# MCU_NAVSS0_UDMAP_0_UDMASS_UDMAP0_CFG_GCFG register map
Vendor: Texas Instruments
Peripheral module from a debugger description file (folder J721S2).
Registers are 32-bit, read-write, reset 0x0 unless marked. A register's access mark holds for its fields unless they carry their own. Offsets are as the file gives them; lines under a group give offsets from that group; [hi:lo] are bit positions; {n}, {i} and the like mark numbered series; 'fields as' and 'values as' point back to an identical list; <NAME> marks a mode.

## MCU_NAVSS0_UDMAP_0_UDMASS_UDMAP0_CFG_GCFG
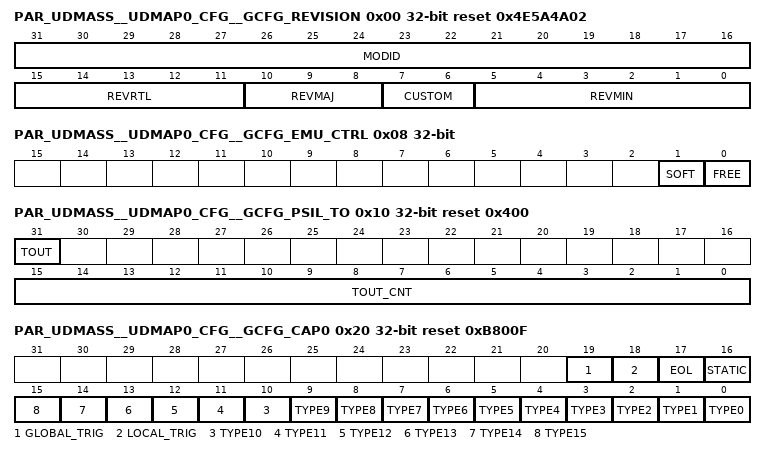
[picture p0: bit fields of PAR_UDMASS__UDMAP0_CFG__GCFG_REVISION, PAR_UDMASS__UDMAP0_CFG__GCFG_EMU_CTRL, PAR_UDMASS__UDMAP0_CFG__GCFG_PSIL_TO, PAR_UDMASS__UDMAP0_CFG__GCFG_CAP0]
0x00 PAR_UDMASS__UDMAP0_CFG__GCFG_REVISION ro reset 0x4E5A4A02 — The Revision Register contains the major and minor revisions for the module.
  [31:16] MODID — Module ID field
  [15:11] REVRTL — RTL revision. Will vary depending on release.
  [10:8] REVMAJ — Major revision
  [7:6] CUSTOM
  [5:0] REVMIN — Minor revision
0x04 PAR_UDMASS__UDMAP0_CFG__GCFG_PERF_CTRL reset 0x40 — The performance control register contains fields which can be used to adjust the performance of the UDMA-P in the system.
  [15:0] TIMEOUT_CNT — This field sets the timeout duration in clock cycles. This field controls the minimum amount of time that an Rx channel will be required to wait when it encounters a buffer starvation condition and the Rx error handling bit is set to 1 (packet is to be preserved - no discard). If the Rx error handling bit in the flow table is cleared, this field will have no effect on the Rx operation. When this field is set to 0, the Rx engine will not force an Rx channel to wait after encountering a starvation event (the feature is disabled). When this field is set to a value other than 0, the Rx engine will force any channel whose associated flow had the Rx error handling bit asserted and which encounters starvation to wait for at least the specified # of clock cycles before coming into context again to check if entries have been added to the Free Queue. This is intended to control potentially debilitating effects on the Rx engine in the UDMAP-P caused by scheduling channels which cannot perform work due to a lack of free descriptor/buffer resources. The exact # of clock cycles between scheduling attempts is not important and will not be exact. The only guarantee is that the # of cycles waited will be at least as large as the timeout_cnt.
0x08 PAR_UDMASS__UDMAP0_CFG__GCFG_EMU_CTRL — The emulation control register is used to control the behavior of the DMA when the emususp input is asserted.
  [1] SOFT, [0] FREE
0x10 PAR_UDMASS__UDMAP0_CFG__GCFG_PSIL_TO reset 0x400 — The PSI-L proxy timeout register controls the timeout watchdog and reports timeout occurrances on PSI-L configuration transactions issued by the built in PSI-L proxy.
  [31] TOUT — Timeout occurred. When set indicates that a timeout has occurred on a config access
  [15:0] TOUT_CNT — Timeout period. Specifies how many cycles to wait before closing up a conifiguration read or write transaction and asserting the tout bit
0x1C PAR_UDMASS__UDMAP0_CFG__GCFG_UTC_CTRL — The external UTC control register provides a mapping of logical to physical thread IDs .
  [15:0] UTC_CHAN_START — This field specifies the starting PSI-L thread number for the external UTC
0x20 PAR_UDMASS__UDMAP0_CFG__GCFG_CAP0 ro reset 0xB800F — The Capabilities Register 0 specifies which standard features this UDMA-P instance supports.
  [19] GLOBAL_TRIG — Global triggers 0 and 1 are supported
  [18] LOCAL_TRIG — Dedicated local trigger is supported
  [17] EOL — EOL field is supported
  [16] STATIC — STATIC field is supported
  [n] TYPE{n} (n=0..15) — Type {n} TR is supported
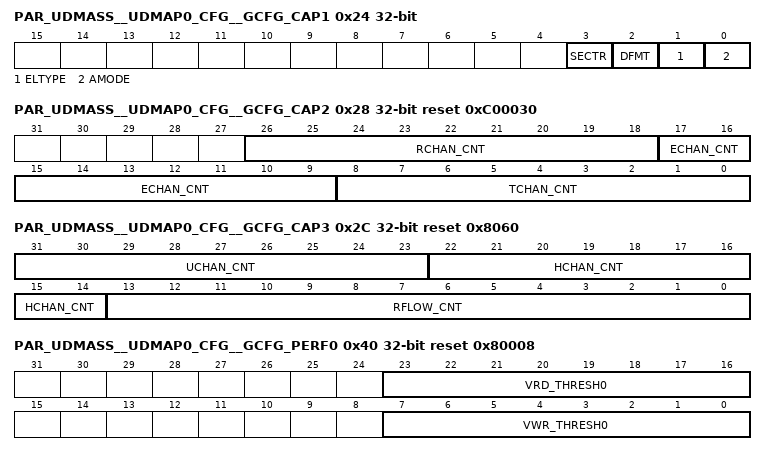
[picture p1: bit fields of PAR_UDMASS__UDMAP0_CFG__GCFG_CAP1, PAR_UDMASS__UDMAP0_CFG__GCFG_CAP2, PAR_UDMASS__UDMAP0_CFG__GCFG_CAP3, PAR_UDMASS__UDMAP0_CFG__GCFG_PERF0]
0x24 PAR_UDMASS__UDMAP0_CFG__GCFG_CAP1 ro — The Capabilities Register 1 specifies which standard features this UDMA-P instance supports.
  [3] SECTR — Maximum second TR function that is supported
  [2] DFMT — Maximum data reformatting function that is supported
  [1] ELTYPE — Maximum element type value that is supported.
  [0] AMODE — The maximum AMODE that is supported. If AMODE is supported then DIR field must be supported for that AMODE.
0x28 PAR_UDMASS__UDMAP0_CFG__GCFG_CAP2 ro reset 0xC00030 — The Capabilities Register 2 specifies how many resources this UDMA-P instance supports.
  [26:18] RCHAN_CNT — Rx internal channel count
  [17:9] ECHAN_CNT — Tx external channel count
  [8:0] TCHAN_CNT — Tx internal channel count
0x2C PAR_UDMASS__UDMAP0_CFG__GCFG_CAP3 ro reset 0x8060 — The Capabilities Register 3 specifies how many resources this UDMA-P instance supports.
  [31:23] UCHAN_CNT — Tx ultra high capacity internal channel count
  [22:14] HCHAN_CNT — Tx high capacity internal channel count
  [13:0] RFLOW_CNT — Rx flow table entry count
0x40 PAR_UDMASS__UDMAP0_CFG__GCFG_PERF0 reset 0x80008 — This register provides thresholds for outstanding virtualized read/write commands from interface mem0
  [23:16] VRD_THRESH0 — Virt read command throttling threshold for mem0. Dispatching will be disabled for virtualized channels whenver the current virtualized read count from this interface meets or exceeds this value.
  [7:0] VWR_THRESH0 — Virt write command throttling threshold for mem0. Dispatching will be disabled for virtualized channels whenver the current virtualized write count from this interface meets or exceeds this value.
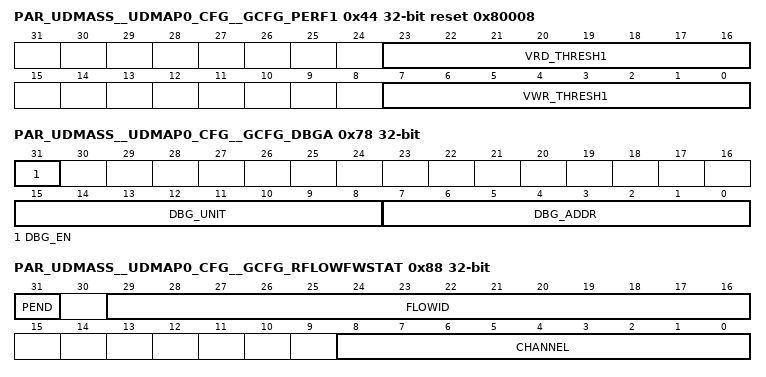
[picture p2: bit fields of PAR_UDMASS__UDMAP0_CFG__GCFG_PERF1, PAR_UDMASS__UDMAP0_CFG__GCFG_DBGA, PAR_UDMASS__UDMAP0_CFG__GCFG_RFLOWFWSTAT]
0x44 PAR_UDMASS__UDMAP0_CFG__GCFG_PERF1 reset 0x80008 — This register provides thresholds for outstanding virtualized read/write commands from interface mem1
  [23:16] VRD_THRESH1 — Virt read command throttling threshold for mem1. Dispatching will be disabled for virtualized channels whenver the current virtualized read count from this interface meets or exceeds this value.
  [7:0] VWR_THRESH1 — Virt write command throttling threshold for mem1. Dispatching will be disabled for virtualized channels whenver the current virtualized write count from this interface meets or exceeds this value.
0x48 PAR_UDMASS__UDMAP0_CFG__GCFG_PERF2 reset 0x100000 — This register provides thresholds for outstanding virtualized read commands from interface memr
  [23:16] VRD_THRESH2 — Virt read command throttling threshold for memr. Dispatching will be disabled for virtualized channels whenver the current virtualized read count from this interface meets or exceeds this value.
0x4C PAR_UDMASS__UDMAP0_CFG__GCFG_PERF3 reset 0x10 — This register provides thresholds for outstanding virtualized write commands from interface memw
  [7:0] VWR_THRESH3 — Virt write command throttling threshold for memw. Dispatching will be disabled for virtualized channels whenver the current virtualized write count from this interface meets or exceeds this value.
0x60 PAR_UDMASS__UDMAP0_CFG__GCFG_PM0 — This register enables or inhibits automatic clock gating to individual sub-blocks
  [31:0] NOGATE_LO — When set inhibits automatic gating of clock.
0x64 PAR_UDMASS__UDMAP0_CFG__GCFG_PM1 — This register enables or inhibits automatic clock gating to individual sub-blocks
  [31:0] NOGATE_HI — When set inhibits automatic gating of clock.
0x78 PAR_UDMASS__UDMAP0_CFG__GCFG_DBGA — This register provides a writable address which allows debug information to be read from the Debug Data Register
  [31] DBG_EN — Debug enable
  [15:8] DBG_UNIT — Selects which unit to read debug information from
  [7:0] DBG_ADDR — Selects offset within unit to access seperate debug registers
0x7C PAR_UDMASS__UDMAP0_CFG__GCFG_DBGD access not given — This register provides read only debug data
  [31:0] DBG_DATA — Provides debug information from various internal units. The value which is read back depends on which unit and register are selected in the Debug Address Register (access R/NA)
0x80 PAR_UDMASS__UDMAP0_CFG__GCFG_RFLOWFWOES reset 0xFFFF — The Rx Flow FW OES Register specifies a destination event number to which an event should be sent if an out of range flow ID is received on a packet.
  [15:0] EVT_NUM — This is the global event number to be generated
0x88 PAR_UDMASS__UDMAP0_CFG__GCFG_RFLOWFWSTAT — The Rx Flow FW Status Register 0 captures information about the thread/channel and received flow ID which failed a range check. Values in this register will remain persistent once an exception has been detected until the pend bit is written back to 0
  [31] PEND — This bit is set whenever the Flow ID firewall detects a Flow ID is out of range for an incoming packet. Once this bit is set, the remaining fields in this register will not be modified. SW is required to write this bit to 0 to allow another exception to be captured.
  [29:16] FLOWID — This is the flow ID that was received on the trapped packet
  [8:0] CHANNEL — This is the channel number on which the trapped packet was received
